# haltium_celldsp register map
Vendor: Nordic Semiconductor; Series: nRFHaltium; File version: 1
Registers are 32-bit, read-write, reset 0x0 unless marked. A register's access mark holds for its fields unless they carry their own. Offsets are from the block's base; [hi:lo] are bit positions; lines under a group give offsets from that group; {n}, {i} and the like mark numbered series; 'fields as' and 'values as' point back to an identical list.

## GLOBAL_MUTEX120 — MUTEX 0
Base 0x4F8D2000
Same registers: GLOBAL_MUTEX130 0x4F927000
{0x400+4i} MUTEX[{i}] (i=0..15) — Description collection: Mutex register
  [0] MUTEX — Mutex register n
    0=Unlocked (Mutex n is in unlocked state); 1=Locked (Mutex n is in locked state)

## GLOBAL_I3C120 — I3C 0
Base 0x4F8D3000
Same registers: GLOBAL_I3C121 0x4F8D4000
0x100 EVENTS_CORE — Event indicating that interrupt triggered at I3C core
  [0] EVENTS_CORE
    0=NotGenerated (Event not generated); 1=Generated (Event generated)
0x104 EVENTS_DMA — Event indicating that interrupt triggered at I3C DMA
  [0] EVENTS_DMA
    values as EVENTS_CORE.EVENTS_CORE
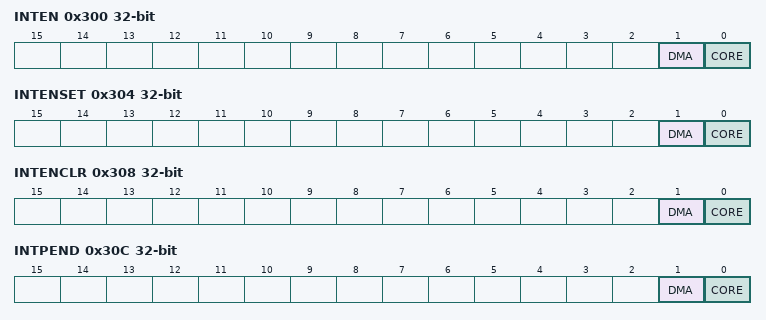
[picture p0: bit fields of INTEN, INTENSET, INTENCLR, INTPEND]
0x300 INTEN — Enable or disable interrupt
  [1] DMA — Enable or disable interrupt for event DMA
    0=Disabled; 1=Enabled
  [0] CORE — Enable or disable interrupt for event CORE
    0=Disabled; 1=Enabled
0x304 INTENSET — Enable interrupt
  [1] DMA — Write '1' to enable interrupt for event DMA
    on read: 0=Disabled (Read: Disabled); 1=Enabled (Read: Enabled) | on write: 1=Set (Enable)
  [0] CORE — Write '1' to enable interrupt for event CORE
    values as DMA
0x308 INTENCLR — Disable interrupt
  [1] DMA — Write '1' to disable interrupt for event DMA
    on read: 0=Disabled (Read: Disabled); 1=Enabled (Read: Enabled) | on write: 1=Clear (Disable)
  [0] CORE — Write '1' to disable interrupt for event CORE
    values as DMA
0x30C INTPEND ro — Pending interrupts
  [1] DMA — Read pending status of interrupt for event DMA
    on read: 0=NotPending (Read: Not pending); 1=Pending (Read: Pending)
  [0] CORE — Read pending status of interrupt for event CORE
    values as DMA
0x400 ENABLE — Enable I3C peripheral.
  [0] EN — Enable
    0=Disabled (I3C peripheral disabled.); 1=Enabled (I3C peripheral enabled.)
0x404 CDR group — Unspecified
  0x00 STARTOFFSET — Start offset of recovered clock
    [15:0] VAL — Value
  0x04 MAXCYCLERATIO — Maximum cycle ratio between SDA/SCL and CDR (clock and data recovery) clock
    [15:0] VAL — Value
  0x08 MAXSKEW — Maximum skew between SCL and SCL in CDR clock cycles
    [7:0] VAL — Value
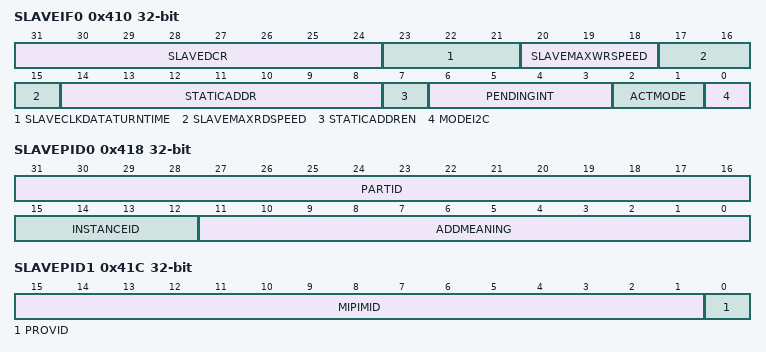
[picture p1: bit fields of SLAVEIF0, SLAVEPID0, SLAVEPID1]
0x410 SLAVEIF0 — I3C slave interface 0
  [31:24] SLAVEDCR — Device Characteristic Register value
  [23:21] SLAVECLKDATATURNTIME — Slave maximum clock data turnaround time
  [20:18] SLAVEMAXWRSPEED — Slave maximum write write rate
  [17:15] SLAVEMAXRDSPEED — Slave maximum read data rate
  [14:8] STATICADDR — Slave static address
  [7] STATICADDREN — Slave static address valid
    0=DISABLED (Unspecified); 1=ENABLED (Unspecified)
  [6:3] PENDINGINT — Pending interrupt information for GETSTATUS CCC
  [2:1] ACTMODE — Slave activity mode for GETSTATUS CCC
  [0] MODEI2C — I2C or I3C mode select signal
    0=DISABLED (Unspecified); 1=ENABLED (Unspecified)
0x414 SLAVEIF1 — I3C slave interface 1
  [0] WAKEUP — Slave wakeup signal
    0=DISABLED (Unspecified); 1=ENABLED (Unspecified)
0x418 SLAVEPID0 — Slave Device Provisioned ID 0
  [31:16] PARTID
  [15:12] INSTANCEID
  [11:0] ADDMEANING — Additional Meaning
0x41C SLAVEPID1 — Slave Device Provisioned ID 1
  [15:1] MIPIMID — MIPI Manufacturer ID
  [0] PROVID — Provisional ID Type Selector
0x420 KEEPSDA — Enable or disable the SDA high-keeper used for Master-to-Slave and Slave-to-Master bus hand-off.
  [0] ENABLE — Enable or disable the SDA high-keeper
    0=Disabled (High-keeper disabled.); 1=Enabled (High-keeper enabled.)
0x424 KEEPSCL — Enable or disable the SCL high-keeper used for Master-to-Slave and Slave-to-Master bus hand-off.
  [0] ENABLE — Enable or disable the SCL high-keeper
    values as KEEPSDA.ENABLE

## GLOBAL_EGU130 — Event generator unit
Base 0x4F92D000
{0x0+4i} TASKS_TRIGGER[{i}] (i=0..15) wo — Description collection: Trigger n for triggering the corresponding TRIGGERED[n] event
  [0] TASKS_TRIGGER — Trigger n for triggering the corresponding TRIGGERED[n] event
    1=Trigger task
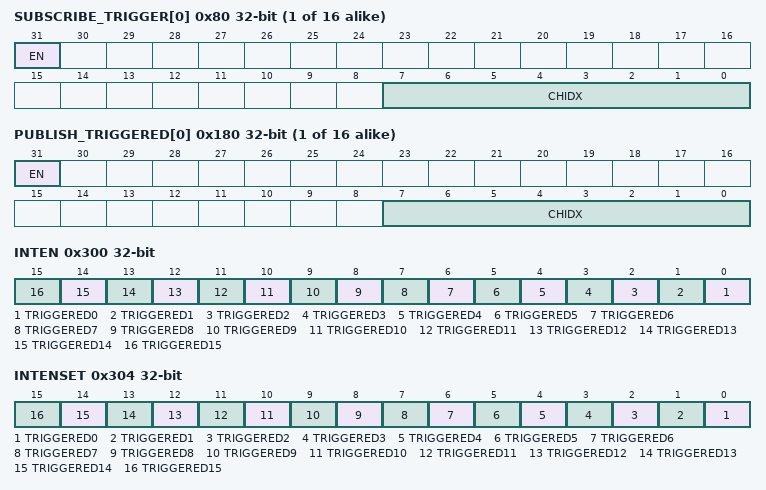
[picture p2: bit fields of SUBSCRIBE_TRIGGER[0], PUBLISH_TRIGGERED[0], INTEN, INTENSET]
{0x80+4i} SUBSCRIBE_TRIGGER[{i}] (i=0..15) — Description collection: Subscribe configuration for task TRIGGER[n]
  [31] EN
    0=Disabled (Disable subscription); 1=Enabled (Enable subscription)
  [7:0] CHIDX — DPPI channel that task TRIGGER[n] will subscribe to
{0x100+4i} EVENTS_TRIGGERED[{i}] (i=0..15) — Description collection: Event number n generated by triggering the corresponding TRIGGER[n] task
  [0] EVENTS_TRIGGERED — Event number n generated by triggering the corresponding TRIGGER[n] task
    0=NotGenerated (Event not generated); 1=Generated (Event generated)
{0x180+4i} PUBLISH_TRIGGERED[{i}] (i=0..15) — Description collection: Publish configuration for event TRIGGERED[n]
  [31] EN
    0=Disabled (Disable publishing); 1=Enabled (Enable publishing)
  [7:0] CHIDX — DPPI channel that event TRIGGERED[n] will publish to
0x300 INTEN — Enable or disable interrupt
  [all] fields
    0=Disabled; 1=Enabled
  [n] TRIGGERED{n} (n=0..15) — Enable or disable interrupt for event TRIGGERED[{n}]
0x304 INTENSET — Enable interrupt
  [all] fields
    on read: 0=Disabled (Read: Disabled); 1=Enabled (Read: Enabled) | on write: 1=Set (Enable)
  [n] TRIGGERED{n} (n=0..15) — Write '1' to enable interrupt for event TRIGGERED[{n}]
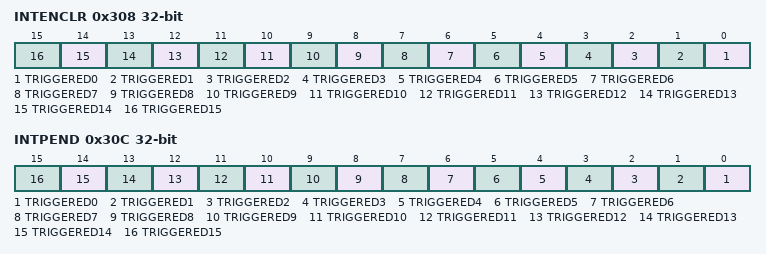
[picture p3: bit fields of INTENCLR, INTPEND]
0x308 INTENCLR — Disable interrupt
  [all] fields
    on read: 0=Disabled (Read: Disabled); 1=Enabled (Read: Enabled) | on write: 1=Clear (Disable)
  [n] TRIGGERED{n} (n=0..15) — Write '1' to disable interrupt for event TRIGGERED[{n}]
0x30C INTPEND ro — Pending interrupts
  [all] fields
    on read: 0=NotPending (Read: Not pending); 1=Pending (Read: Pending)
  [n] TRIGGERED{n} (n=0..15) — Read pending status of interrupt for event TRIGGERED[{n}]

## GLOBAL_GPIOINTERNAL — GPIO Internal
Base 0x4F939E00
0x40 LATCHCLRWAITCNT reset 0x2 — Select the number of wait cycles inserted on the bus when a LATCH register is cleared.
  [1:0] LATCHCLRWAITCNT
0x44 FORCELDETECTLOWCNT reset 0x8 — Select the number of cycles that LDETECT is forced low after clearing a LATCH register.
  [3:0] FORCELDETECTLOWCNT
0x48 RESET — Reset all GPIO registers.
  [0] RESET
    1=RESET (Trigger reset); 0=NA (No effect)
0x4C SENSECONFIGCHANGECNT reset 0x3 — Selects the number of cycles before the SENSE configuration takes effect when it is changed. Setting this register lower than the reset value can lead to unwanted LATCH set when SENSE and INPUT fields (PIN[n].CNF) are changed simultaneously.
  [2:0] SENSECONFIGCHANGECNT — Selects the number of cycles before the SENSE configuration takes effect when it is changed.
0x50 PCGC group — Unspecified
  0x00 TRIGZEROPENALTY ro — Trigger zero penalty
    [0] TRIGGER
      1=Enable (Trigger zero penalty)
  0x04 TRIGFULLPENALTY ro — Trigger full penalty
    [0] TRIGGER
      1=Enable (Trigger full penalty)
  {0x8+4j} PENALTY[{j}] (j=0..1) ro — Description collection: Penalty level for power/clock pair n
    [7:0] PENALTY — Penalty level
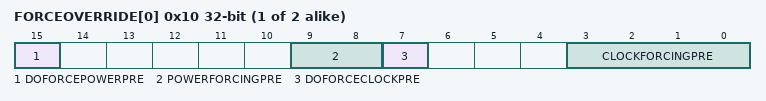
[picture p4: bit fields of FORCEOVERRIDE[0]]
  {0x10+4j} FORCEOVERRIDE[{j}] (j=0..1) ro — Description collection: Force override of power/clock pair n
    [15] DOFORCEPOWERPRE, [9:8] POWERFORCINGPRE, [7] DOFORCECLOCKPRE, [3:0] CLOCKFORCINGPRE
